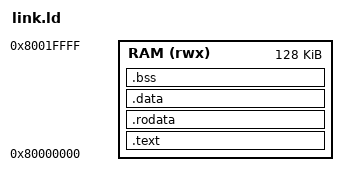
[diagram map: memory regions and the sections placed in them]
/* Simple linker script for RV32I baremetal */
OUTPUT_ARCH(riscv)
ENTRY(_start)

MEMORY
{
    RAM (rwx) : ORIGIN = 0x80000000, LENGTH = 128K
}

SECTIONS
{
    .text : {
        *(.text*)
    } > RAM

    .rodata : {
        *(.rodata*)
    } > RAM

    .data : {
        *(.data*)
    } > RAM

    .bss : {
        *(.bss*)
        *(COMMON)
    } > RAM

    /* Stack grows downward from end of RAM */
    . = ORIGIN(RAM) + LENGTH(RAM);
    _stack_top = .;
}
